VERSION ""

NS_ :

BS_:

BU_: WDAQ MTI600 Datalogger FSGDatalogger GroundSpeed RES Jetson ACM RC Flasher

BO_ 865 Pump1Command: 8 RC
 SG_ Speed : 0|16@1+ (0.001,0.0) [0.0|65.0] "rpm"  Vector__XXX

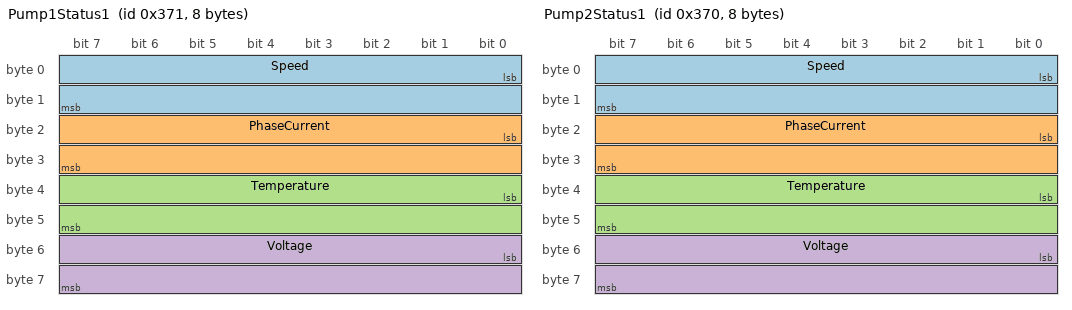
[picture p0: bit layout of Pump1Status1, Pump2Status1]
BO_ 881 Pump1Status1: 8 Pump1
 SG_ Speed : 0|16@1+ (0.001,0.0) [0.0|65.0] "rpm"  Vector__XXX
 SG_ PhaseCurrent : 16|16@1+ (10.0,0.0) [-300.0|300.0] "A"  Vector__XXX
 SG_ Temperature : 32|16@1+ (10.0,0.0) [0.0|200.0] "C"  Vector__XXX
 SG_ Voltage : 48|16@1+ (1.0,0.0) [0.0|65000.0] "mV"  Vector__XXX

BO_ 1025 Pump1Diagnostic: 8 Pump1
 SG_ Header : 0|8@1+ (1.0,0.0) [0.0|256.0] ""  Vector__XXX
 SG_ Data : 8|32@1+ (1.0,0.0) [0.0|16000.0] ""  Vector__XXX

BO_ 864 Pump2Command: 8 RC
 SG_ Speed : 0|16@1+ (0.001,0.0) [0.0|65.0] "rpm"  Vector__XXX

BO_ 880 Pump2Status1: 8 Pump2
 SG_ Speed : 0|16@1+ (0.001,0.0) [0.0|65.0] "rpm"  Vector__XXX
 SG_ PhaseCurrent : 16|16@1+ (10.0,0.0) [-300.0|300.0] "A"  Vector__XXX
 SG_ Temperature : 32|16@1+ (10.0,0.0) [0.0|200.0] "C"  Vector__XXX
 SG_ Voltage : 48|16@1+ (1.0,0.0) [0.0|65000.0] "mV"  Vector__XXX

BO_ 1024 Pump2Diagnostic: 8 Pump2
 SG_ Header : 0|8@1+ (1.0,0.0) [0.0|256.0] ""  Vector__XXX
 SG_ Data : 8|32@1+ (1.0,0.0) [0.0|16000.0] ""  Vector__XXX

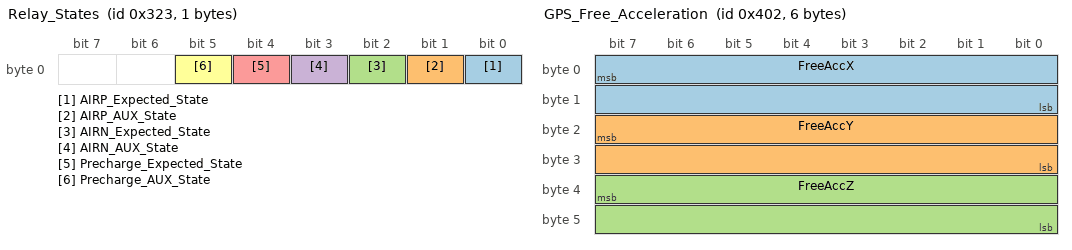
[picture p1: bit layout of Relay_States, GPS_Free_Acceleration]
BO_ 803 Relay_States: 1 ACM
 SG_ AIRP_Expected_State : 0|1@1+ (1.0,0.0) [0.0|1.0] ""  RC,WDAQ
 SG_ AIRP_AUX_State : 1|1@1+ (1.0,0.0) [0.0|1.0] ""  RC,WDAQ
 SG_ AIRN_Expected_State : 2|1@1+ (1.0,0.0) [0.0|1.0] ""  RC,WDAQ
 SG_ AIRN_AUX_State : 3|1@1+ (1.0,0.0) [0.0|1.0] ""  RC,WDAQ
 SG_ Precharge_Expected_State : 4|1@1+ (1.0,0.0) [0.0|1.0] ""  RC,WDAQ
 SG_ Precharge_AUX_State : 5|1@1+ (1.0,0.0) [0.0|1.0] ""  RC,WDAQ

BO_ 1104 Datalogger_Start: 0 RC

BO_ 1026 GPS_Free_Acceleration: 6 MTI600
 SG_ FreeAccX : 7|16@0- (0.00390625,0) [-100.0|100.0] "m/s^2"  WDAQ,Jetson
 SG_ FreeAccY : 23|16@0- (0.00390625,0) [-100.0|100.0] "m/s^2"  WDAQ,Jetson
 SG_ FreeAccZ : 39|16@0- (0.00390625,0) [-100.0|100.0] "m/s^2"  WDAQ,Jetson

BO_ 1045 GPS_StatusWord: 4 MTI600
 SG_ StatusWord : 7|32@0+ (1.0,0) [0.0|4294967295.0] ""  WDAQ,Jetson

BO_ 1046 GPS_Error: 1 MTI600
 SG_ ErrorCode : 7|8@0+ (1.0,0) [0.0|255.0] ""  WDAQ,Jetson

BO_ 1027 GPS_Warning: 1 MTI600
 SG_ WarningCode : 7|8@0+ (1.0,0) [0.0|255.0] ""  WDAQ,Jetson

BO_ 1028 GPS_Sample_Time: 4 MTI600
 SG_ SampleTime : 7|32@0+ (1.0,0) [0.0|4294967295.0] "100us"  WDAQ,Jetson

BO_ 1029 GPS_Group_Counter: 2 MTI600
 SG_ Counter : 7|16@0+ (1.0,0) [0.0|65535.0] ""  WDAQ,Jetson

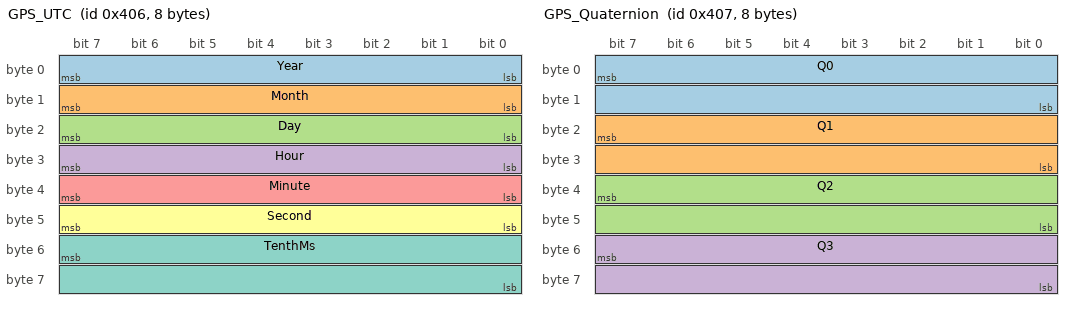
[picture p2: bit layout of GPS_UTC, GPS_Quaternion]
BO_ 1030 GPS_UTC: 8 MTI600
 SG_ Year : 7|8@0+ (1.0,0) [0.0|255.0] ""  WDAQ,Jetson
 SG_ Month : 15|8@0+ (1.0,0) [1.0|12.0] ""  WDAQ,Jetson
 SG_ Day : 23|8@0+ (1.0,0) [1.0|31.0] ""  WDAQ,Jetson
 SG_ Hour : 31|8@0+ (1.0,0) [0.0|24.0] ""  WDAQ,Jetson
 SG_ Minute : 39|8@0+ (1.0,0) [0.0|60.0] ""  WDAQ,Jetson
 SG_ Second : 47|8@0+ (1.0,0) [0.0|60.0] ""  WDAQ,Jetson
 SG_ TenthMs : 55|16@0+ (1.0,0) [0.0|10000.0] "0.1ms"  WDAQ,Jetson

BO_ 1031 GPS_Quaternion: 8 MTI600
 SG_ Q0 : 7|16@0- (3.0517578125e-05,0) [-1.0|1.0] ""  WDAQ,Jetson
 SG_ Q1 : 23|16@0- (3.0517578125e-05,0) [-1.0|1.0] ""  WDAQ,Jetson
 SG_ Q2 : 39|16@0- (3.0517578125e-05,0) [-1.0|1.0] ""  WDAQ,Jetson
 SG_ Q3 : 55|16@0- (3.0517578125e-05,0) [-1.0|1.0] ""  WDAQ,Jetson

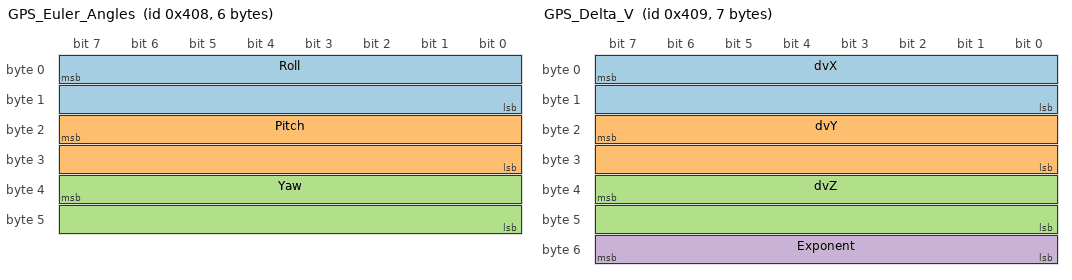
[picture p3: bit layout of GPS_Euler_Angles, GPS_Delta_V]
BO_ 1032 GPS_Euler_Angles: 6 MTI600
 SG_ Roll : 7|16@0- (0.0078125,0) [-180.0|180.0] "deg"  WDAQ,Jetson
 SG_ Pitch : 23|16@0- (0.0078125,0) [-90.0|90.0] "deg"  WDAQ,Jetson
 SG_ Yaw : 39|16@0- (0.0078125,0) [-180.0|180.0] "deg"  WDAQ,Jetson

BO_ 1033 GPS_Delta_V: 7 MTI600
 SG_ dvX : 7|16@0- (7.62939453125e-06,0) [-0.25|0.25] "m/s"  WDAQ,Jetson
 SG_ dvY : 23|16@0- (7.62939453125e-06,0) [-0.25|0.25] "m/s"  WDAQ,Jetson
 SG_ dvZ : 39|16@0- (7.62939453125e-06,0) [-0.25|0.25] "m/s"  WDAQ,Jetson
 SG_ Exponent : 55|8@0+ (1.0,0) [0.0|255.0] ""  WDAQ,Jetson

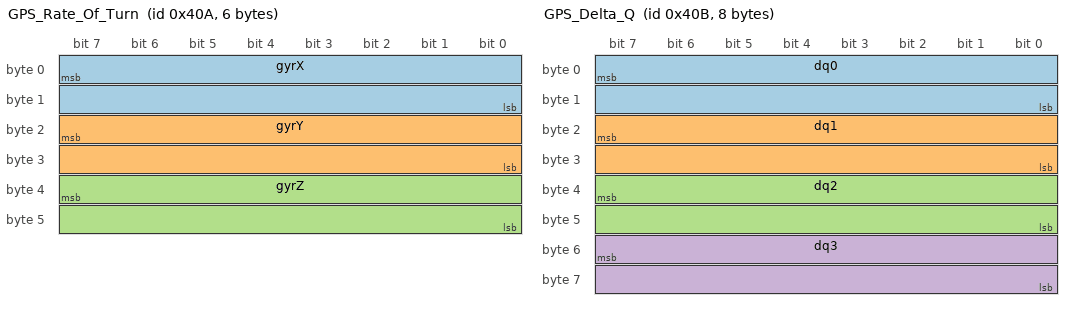
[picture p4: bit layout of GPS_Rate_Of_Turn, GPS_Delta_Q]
BO_ 1034 GPS_Rate_Of_Turn: 6 MTI600
 SG_ gyrX : 7|16@0- (0.001953125,0) [-35.0|35.0] "rad/s"  WDAQ,Jetson
 SG_ gyrY : 23|16@0- (0.001953125,0) [-35.0|35.0] "rad/s"  WDAQ,Jetson
 SG_ gyrZ : 39|16@0- (0.001953125,0) [-35.0|35.0] "rad/s"  WDAQ,Jetson

BO_ 1035 GPS_Delta_Q: 8 MTI600
 SG_ dq0 : 7|16@0- (3.0518509476e-05,0) [-1.0|1.0] ""  WDAQ,Jetson
 SG_ dq1 : 23|16@0- (3.0518509476e-05,0) [-1.0|1.0] ""  WDAQ,Jetson
 SG_ dq2 : 39|16@0- (3.0518509476e-05,0) [-1.0|1.0] ""  WDAQ,Jetson
 SG_ dq3 : 55|16@0- (3.0518509476e-05,0) [-1.0|1.0] ""  WDAQ,Jetson

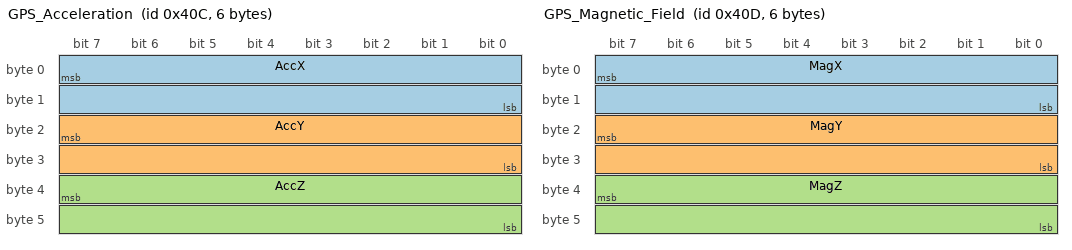
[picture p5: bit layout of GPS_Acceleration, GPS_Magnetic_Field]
BO_ 1036 GPS_Acceleration: 6 MTI600
 SG_ AccX : 7|16@0- (0.00390625,0) [-100.0|100.0] "m/s^2"  WDAQ,Jetson
 SG_ AccY : 23|16@0- (0.00390625,0) [-100.0|100.0] "m/s^2"  WDAQ,Jetson
 SG_ AccZ : 39|16@0- (0.00390625,0) [-100.0|100.0] "m/s^2"  WDAQ,Jetson

BO_ 1037 GPS_Magnetic_Field: 6 MTI600
 SG_ MagX : 7|16@0- (0.0009765625,0) [-32.0|32.0] "a.u."  WDAQ,Jetson
 SG_ MagY : 23|16@0- (0.0009765625,0) [-32.0|32.0] "a.u."  WDAQ,Jetson
 SG_ MagZ : 39|16@0- (0.0009765625,0) [-32.0|32.0] "a.u."  WDAQ,Jetson

BO_ 1038 GPS_Temperature: 2 MTI600
 SG_ Temperature : 7|16@0- (0.00390625,0) [-40.0|85.0] "degC"  WDAQ,Jetson

BO_ 1039 GPS_Baro_Pressure: 4 MTI600
 SG_ Pressure : 7|32@0+ (3.0517578125e-05,0) [30000.0|125000.0] "Pa"  WDAQ,Jetson

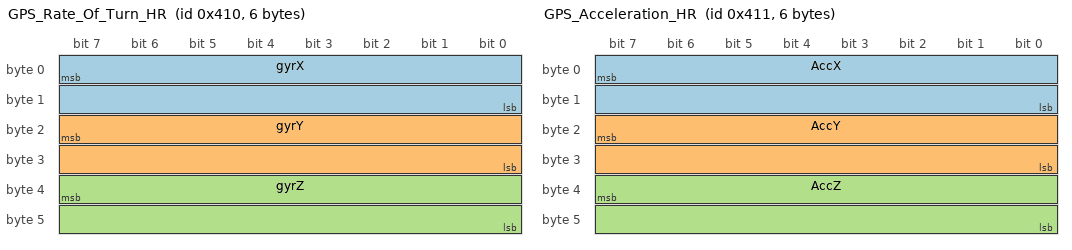
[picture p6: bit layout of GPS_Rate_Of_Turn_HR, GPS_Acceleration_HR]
BO_ 1040 GPS_Rate_Of_Turn_HR: 6 MTI600
 SG_ gyrX : 7|16@0- (0.001953125,0) [-35.0|35.0] "rad/s"  WDAQ,Jetson
 SG_ gyrY : 23|16@0- (0.001953125,0) [-35.0|35.0] "rad/s"  WDAQ,Jetson
 SG_ gyrZ : 39|16@0- (0.001953125,0) [-35.0|35.0] "rad/s"  WDAQ,Jetson

BO_ 1041 GPS_Acceleration_HR: 6 MTI600
 SG_ AccX : 7|16@0- (0.00390625,0) [-100.0|100.0] "m/s^2"  WDAQ,Jetson
 SG_ AccY : 23|16@0- (0.00390625,0) [-100.0|100.0] "m/s^2"  WDAQ,Jetson
 SG_ AccZ : 39|16@0- (0.00390625,0) [-100.0|100.0] "m/s^2"  WDAQ,Jetson

BO_ 1042 GPS_Lat_Lon: 8 MTI600
 SG_ Latitude : 7|32@0- (5.9604644775e-08,0) [-90.0|90.0] "deg"  WDAQ,Jetson
 SG_ Longitude : 39|32@0- (1.1920928955e-07,0) [-180.0|180.0] "deg"  WDAQ,Jetson

BO_ 1043 GPS_Altitude_Ellipsoid: 4 MTI600
 SG_ AltitudeEllipsoid : 7|32@0+ (3.0517578125e-05,0) [0.0|50000.0] "m"  WDAQ,Jetson

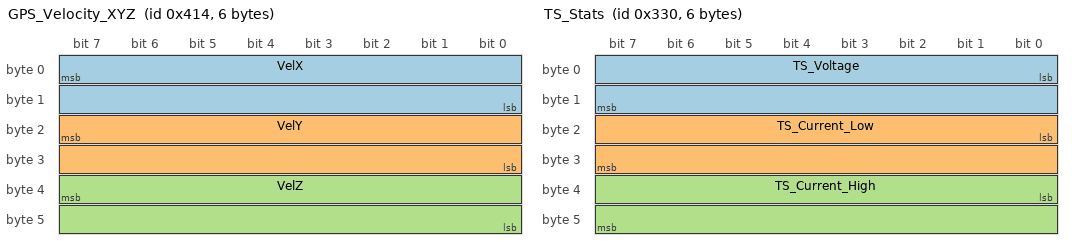
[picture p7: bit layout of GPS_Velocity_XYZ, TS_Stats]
BO_ 1044 GPS_Velocity_XYZ: 6 MTI600
 SG_ VelX : 7|16@0- (0.015625,0) [-500.0|500.0] "m/s"  WDAQ,Jetson
 SG_ VelY : 23|16@0- (0.015625,0) [-500.0|500.0] "m/s"  WDAQ,Jetson
 SG_ VelZ : 39|16@0- (0.015625,0) [-500.0|500.0] "m/s"  WDAQ,Jetson

BO_ 816 TS_Stats: 6 ACM
 SG_ TS_Voltage : 0|16@1+ (1.0,0.0) [0.0|1035.0] "V"  RC,WDAQ
 SG_ TS_Current_Low : 16|16@1- (0.01,0.0) [-32768.0|32767.0] "A"  RC,WDAQ
 SG_ TS_Current_High : 32|16@1- (0.01,0.0) [-32768.0|32767.0] "A"  RC,WDAQ

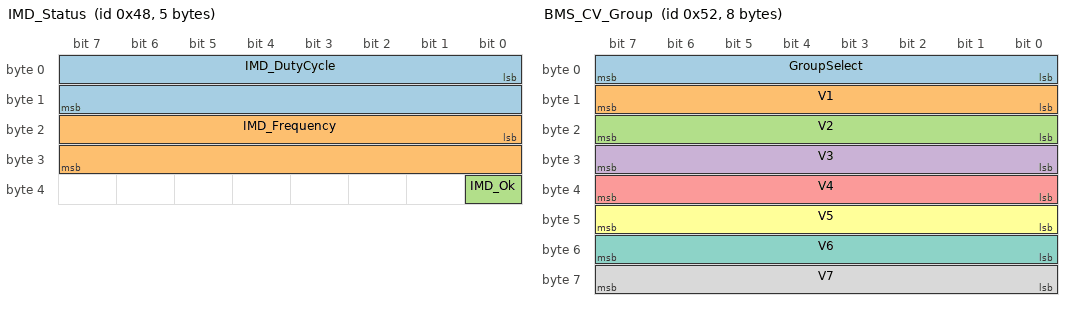
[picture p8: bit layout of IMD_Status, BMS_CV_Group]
BO_ 72 IMD_Status: 5 ACM
 SG_ IMD_DutyCycle : 0|16@1+ (0.01,0.0) [0.0|100.0] "%"  WDAQ
 SG_ IMD_Frequency : 16|16@1+ (0.01,0.0) [0.0|50.0] "Hz"  WDAQ
 SG_ IMD_Ok : 32|1@1+ (1.0,0.0) [0.0|1.0] ""  WDAQ

BO_ 81 BMS_Cell_Open_Wire: 1 ACM
 SG_ Cell : 0|8@1+ (1.0,0.0) [0.0|138.0] ""  WDAQ

BO_ 82 BMS_CV_Group: 8 ACM
 SG_ GroupSelect : 0|8@1+ (1.0,0.0) [0.0|20.0] ""  WDAQ
 SG_ V1 : 8|8@1+ (0.01,3.0) [3.0|4.35] "V"  WDAQ
 SG_ V2 : 16|8@1+ (0.01,3.0) [3.0|4.35] "V"  WDAQ
 SG_ V3 : 24|8@1+ (0.01,3.0) [3.0|4.35] "V"  WDAQ
 SG_ V4 : 32|8@1+ (0.01,3.0) [3.0|4.35] "V"  WDAQ
 SG_ V5 : 40|8@1+ (0.01,3.0) [3.0|4.35] "V"  WDAQ
 SG_ V6 : 48|8@1+ (0.01,3.0) [3.0|4.35] "V"  WDAQ
 SG_ V7 : 56|8@1+ (0.01,3.0) [3.0|4.35] "V"  WDAQ

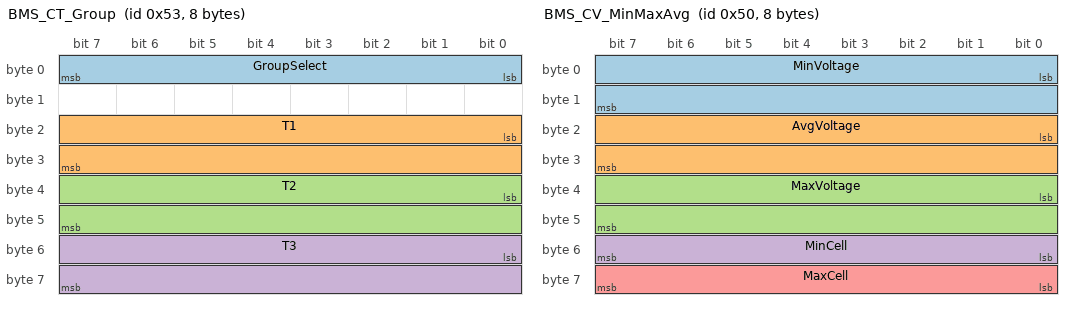
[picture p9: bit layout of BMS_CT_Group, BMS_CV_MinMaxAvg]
BO_ 83 BMS_CT_Group: 8 ACM
 SG_ GroupSelect : 0|8@1+ (1.0,0.0) [0.0|20.0] ""  WDAQ
 SG_ T1 : 16|16@1+ (0.01,0.0) [0.0|100.0] "C"  WDAQ
 SG_ T2 : 32|16@1+ (0.01,0.0) [0.0|100.0] "C"  WDAQ
 SG_ T3 : 48|16@1+ (0.01,0.0) [0.0|100.0] "C"  WDAQ

BO_ 80 BMS_CV_MinMaxAvg: 8 ACM
 SG_ MinVoltage : 0|16@1+ (0.0001,0.0) [0.0|6.5535] "V"  WDAQ
 SG_ AvgVoltage : 16|16@1+ (0.0001,0.0) [0.0|6.5535] "V"  WDAQ
 SG_ MaxVoltage : 32|16@1+ (0.0001,0.0) [0.0|6.5535] "V"  WDAQ
 SG_ MinCell : 48|8@1+ (1.0,0.0) [0.0|138.0] ""  WDAQ
 SG_ MaxCell : 56|8@1+ (1.0,0.0) [0.0|138.0] ""  WDAQ

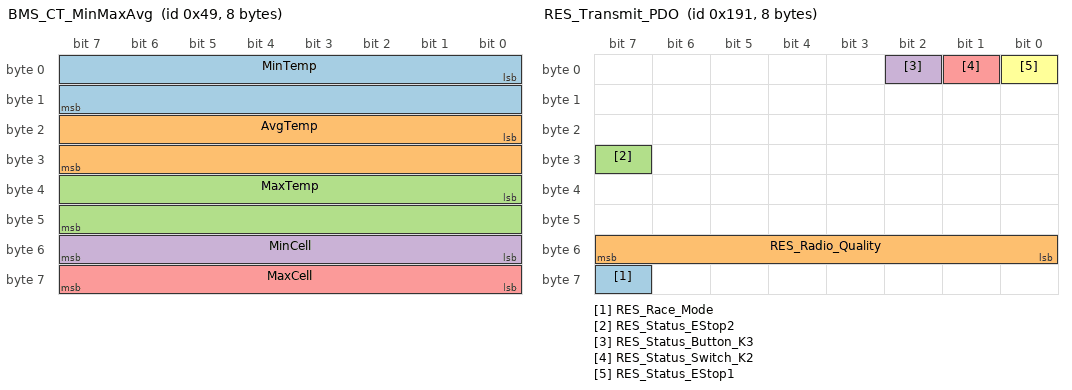
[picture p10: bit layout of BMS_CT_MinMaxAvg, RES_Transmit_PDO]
BO_ 73 BMS_CT_MinMaxAvg: 8 ACM
 SG_ MinTemp : 0|16@1+ (0.01,0.0) [0.0|100.0] "C"  WDAQ
 SG_ AvgTemp : 16|16@1+ (0.01,0.0) [0.0|100.0] "C"  WDAQ
 SG_ MaxTemp : 32|16@1+ (0.01,0.0) [0.0|100.0] "C"  WDAQ
 SG_ MinCell : 48|8@1+ (1.0,0.0) [0.0|138.0] ""  WDAQ
 SG_ MaxCell : 56|8@1+ (1.0,0.0) [0.0|138.0] ""  WDAQ

BO_ 261 DFU_Requested: 1 Flasher
 SG_ DFU_Controller : 0|8@1+ (1.0,0.0) [0.0|4.0] ""  ACM,FC,RC,WDAQ

BO_ 260 DFU_Ack: 0 Flasher

BO_ 117 RC_SDC_State: 1 RC
 SG_ SDC_Point : 0|8@1+ (1.0,0.0) [0.0|255.0] ""  ACM,FC,WDAQ

BO_ 128 RES_Sync: 8 RC

BO_ 401 RES_Transmit_PDO: 8 RES
 SG_ RES_Race_Mode : 63|1@1+ (1.0,0.0) [0.0|1.0] ""  RC
 SG_ RES_Radio_Quality : 48|8@1+ (1.0,0.0) [0.0|100.0] "%"  RC
 SG_ RES_Status_EStop2 : 31|1@1+ (1.0,0.0) [0.0|1.0] ""  RC
 SG_ RES_Status_Button_K3 : 2|1@1+ (1.0,0.0) [0.0|0.0] ""  Jetson,RC
 SG_ RES_Status_Switch_K2 : 1|1@1+ (1.0,0.0) [0.0|1.0] ""  Jetson,RC
 SG_ RES_Status_EStop1 : 0|1@1+ (1.0,0.0) [0.0|1.0] ""  Jetson,RC

BO_ 0 RES_Operational_Mode: 2 RC
 SG_ RES_Node_ID : 8|8@1+ (1.0,0.0) [0.0|64.0] ""  RES
 SG_ RES_Requested_State : 0|8@1+ (1.0,0.0) [0.0|1.0] ""  RES

BO_ 1809 RES_Init: 1 RES
 SG_ RES_Init : 0|8@1+ (1.0,0.0) [0.0|0.0] ""  RC

BO_ 23 Jetson_Error: 1 RC
 SG_ Jetson_Error : 0|8@1+ (1.0,0.0) [0.0|255.0] ""  RC

BO_ 21 ACM_State: 1 ACM
 SG_ ACM_Error : 0|8@1+ (1.0,0.0) [0.0|255.0] ""  RC

BO_ 118 ACM_SDC_State: 1 RC
 SG_ SDC_Point : 0|8@1+ (1.0,0.0) [0.0|255.0] ""  RC,WDAQ

BO_ 24 RC_State: 2 RC
 SG_ RC_State : 0|8@1+ (1.0,0.0) [0.0|7.0] ""  ACM,WDAQ
 SG_ RC_Error : 8|8@1+ (1.0,0.0) [0.0|255.0] ""  ACM,WDAQ

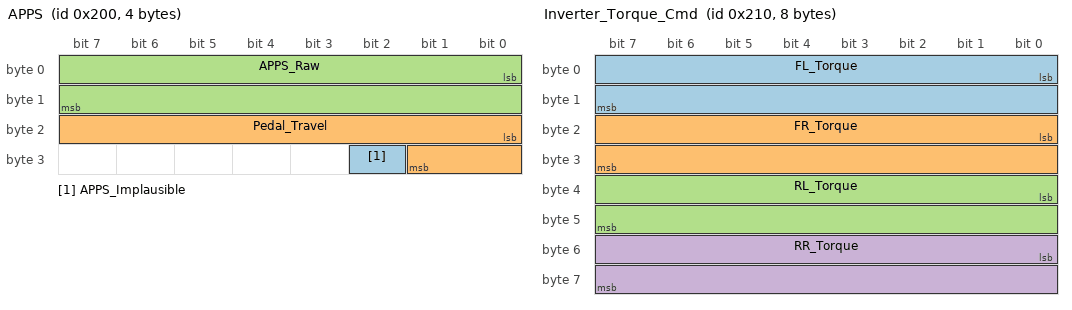
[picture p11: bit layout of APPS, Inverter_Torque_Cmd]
BO_ 512 APPS: 4 RC
 SG_ APPS_Implausible : 26|1@1+ (1.0,0.0) [0.0|1.0] ""  WDAQ
 SG_ Pedal_Travel : 16|10@1+ (0.1,0.0) [0.0|100.0] "%"  WDAQ
 SG_ APPS_Raw : 0|16@1+ (1.0,0.0) [0.0|65535.0] ""  WDAQ

BO_ 530 BSPD: 2 RC
 SG_ BSPD_Current : 0|16@1+ (1.0,0.0) [0.0|4095.0] "counts"  WDAQ

BO_ 528 Inverter_Torque_Cmd: 8 RC
 SG_ FL_Torque : 0|16@1+ (0.2,-6400.0) [-6400.0|6451.0] "Nm"  WDAQ
 SG_ FR_Torque : 16|16@1+ (0.2,-6400.0) [-6400.0|6451.0] "Nm"  WDAQ
 SG_ RL_Torque : 32|16@1+ (0.2,-6400.0) [-6400.0|6451.0] "Nm"  WDAQ
 SG_ RR_Torque : 48|16@1+ (0.2,-6400.0) [-6400.0|6451.0] "Nm"  WDAQ

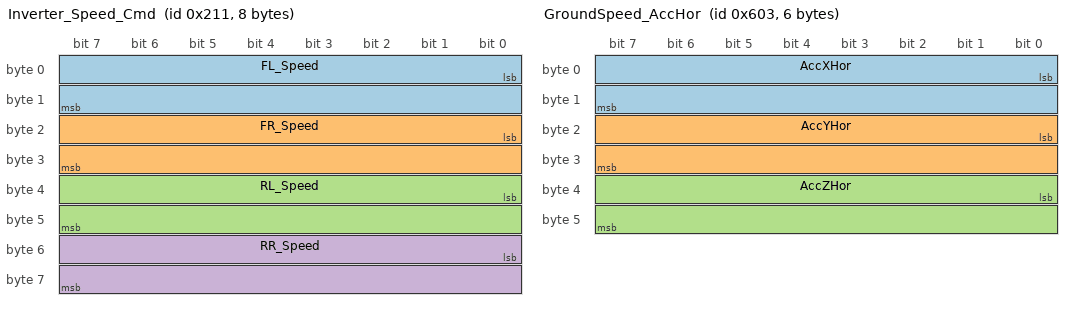
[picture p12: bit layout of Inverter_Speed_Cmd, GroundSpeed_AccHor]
BO_ 529 Inverter_Speed_Cmd: 8 RC
 SG_ FL_Speed : 0|16@1+ (1.0,-32000.0) [-32000.0|32255.0] "RPM"  WDAQ
 SG_ FR_Speed : 16|16@1+ (1.0,-32000.0) [-32000.0|32255.0] "RPM"  WDAQ
 SG_ RL_Speed : 32|16@1+ (1.0,-32000.0) [-32000.0|32255.0] "RPM"  WDAQ
 SG_ RR_Speed : 48|16@1+ (1.0,-32000.0) [-32000.0|32255.0] "RPM"  WDAQ

BO_ 1538 GroundSpeed_PitchAndRoll: 4 GroundSpeed
 SG_ Roll : 0|16@1- (0.003,0.0) [-90.0|90.0] "deg"  WDAQ,Jetson
 SG_ Pitch : 16|16@1- (0.003,0.0) [-90.0|90.0] "deg"  WDAQ,Jetson

BO_ 1539 GroundSpeed_AccHor: 6 GroundSpeed
 SG_ AccXHor : 0|16@1- (0.02,0.0) [-200.0|200.0] "m/s^2"  WDAQ,Jetson
 SG_ AccYHor : 16|16@1- (0.02,0.0) [-200.0|200.0] "m/s^2"  WDAQ,Jetson
 SG_ AccZHor : 32|16@1- (0.02,0.0) [-200.0|200.0] "m/s^2"  WDAQ,Jetson

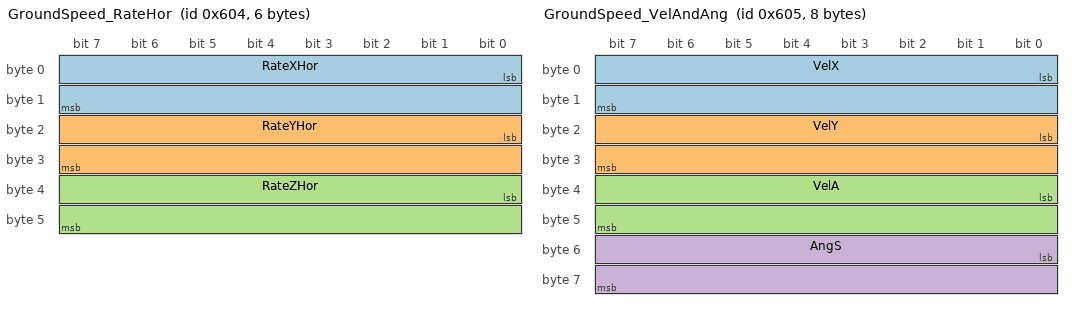
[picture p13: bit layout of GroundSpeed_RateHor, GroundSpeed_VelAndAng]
BO_ 1540 GroundSpeed_RateHor: 6 GroundSpeed
 SG_ RateXHor : 0|16@1- (0.02,0.0) [-500.0|500.0] "deg/s"  WDAQ,Jetson
 SG_ RateYHor : 16|16@1- (0.02,0.0) [-500.0|500.0] "deg/s"  WDAQ,Jetson
 SG_ RateZHor : 32|16@1- (0.02,0.0) [-500.0|500.0] "deg/s"  WDAQ,Jetson

BO_ 1541 GroundSpeed_VelAndAng: 8 GroundSpeed
 SG_ VelX : 0|16@1- (0.02,0.0) [-450.0|450.0] "km/h"  WDAQ,Jetson
 SG_ VelY : 16|16@1- (0.02,0.0) [-100.0|100.0] "km/h"  WDAQ,Jetson
 SG_ VelA : 32|16@1- (0.02,0.0) [0.0|450.0] "km/h"  WDAQ,Jetson
 SG_ AngS : 48|16@1- (0.003,0.0) [-40.0|40.0] "deg"  WDAQ,Jetson

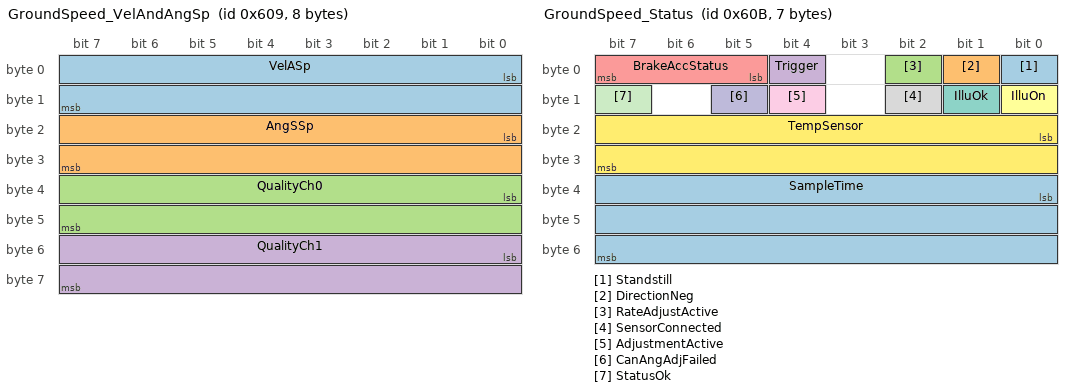
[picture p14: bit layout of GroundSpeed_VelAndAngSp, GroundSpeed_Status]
BO_ 1545 GroundSpeed_VelAndAngSp: 8 GroundSpeed
 SG_ VelASp : 0|16@1- (0.02,0.0) [0.0|450.0] "km/h"  WDAQ,Jetson
 SG_ AngSSp : 16|16@1- (0.003,0.0) [-40.0|40.0] "deg"  WDAQ,Jetson
 SG_ QualityCh0 : 32|16@1+ (1.0,0.0) [0.0|65535.0] ""  WDAQ,Jetson
 SG_ QualityCh1 : 48|16@1+ (1.0,0.0) [0.0|65535.0] ""  WDAQ,Jetson

BO_ 1547 GroundSpeed_Status: 7 GroundSpeed
 SG_ Standstill : 0|1@1+ (1.0,0.0) [0.0|1.0] ""  WDAQ,Jetson
 SG_ DirectionNeg : 1|1@1+ (1.0,0.0) [0.0|1.0] ""  WDAQ,Jetson
 SG_ RateAdjustActive : 2|1@1+ (1.0,0.0) [0.0|1.0] ""  WDAQ,Jetson
 SG_ Trigger : 4|1@1+ (1.0,0.0) [0.0|1.0] ""  WDAQ,Jetson
 SG_ BrakeAccStatus : 5|3@1+ (1.0,0.0) [0.0|5.0] ""  WDAQ,Jetson
 SG_ IlluOn : 8|1@1+ (1.0,0.0) [0.0|1.0] ""  WDAQ,Jetson
 SG_ IlluOk : 9|1@1+ (1.0,0.0) [0.0|1.0] ""  WDAQ,Jetson
 SG_ SensorConnected : 10|1@1+ (1.0,0.0) [0.0|1.0] ""  WDAQ,Jetson
 SG_ AdjustmentActive : 12|1@1+ (1.0,0.0) [0.0|1.0] ""  WDAQ,Jetson
 SG_ CanAngAdjFailed : 13|1@1+ (1.0,0.0) [0.0|1.0] ""  WDAQ,Jetson
 SG_ StatusOk : 15|1@1+ (1.0,0.0) [0.0|1.0] ""  WDAQ,Jetson
 SG_ TempSensor : 16|16@1- (0.1,0.0) [-20.0|85.0] "C"  WDAQ,Jetson
 SG_ SampleTime : 32|24@1+ (0.001,0.0) [0.0|16777.215] "s"  WDAQ,Jetson

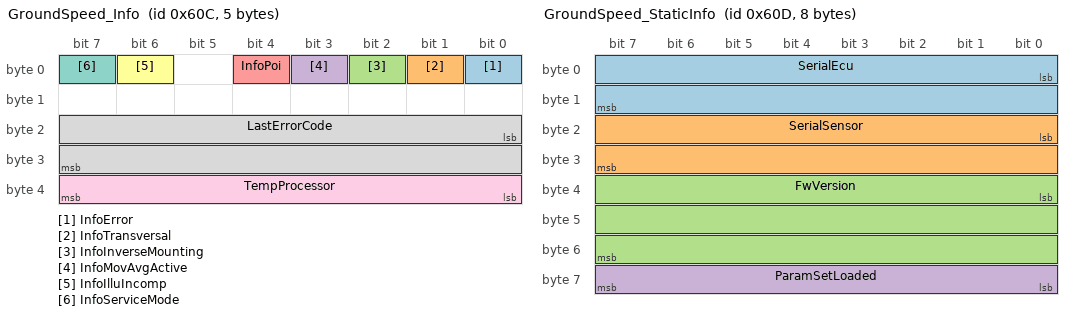
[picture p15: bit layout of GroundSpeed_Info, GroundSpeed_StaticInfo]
BO_ 1548 GroundSpeed_Info: 5 GroundSpeed
 SG_ InfoError : 0|1@1+ (1.0,0.0) [0.0|1.0] ""  WDAQ,Jetson
 SG_ InfoTransversal : 1|1@1+ (1.0,0.0) [0.0|1.0] ""  WDAQ,Jetson
 SG_ InfoInverseMounting : 2|1@1+ (1.0,0.0) [0.0|1.0] ""  WDAQ,Jetson
 SG_ InfoMovAvgActive : 3|1@1+ (1.0,0.0) [0.0|1.0] ""  WDAQ,Jetson
 SG_ InfoPoi : 4|1@1+ (1.0,0.0) [0.0|1.0] ""  WDAQ,Jetson
 SG_ InfoIlluIncomp : 6|1@1+ (1.0,0.0) [0.0|1.0] ""  WDAQ,Jetson
 SG_ InfoServiceMode : 7|1@1+ (1.0,0.0) [0.0|1.0] ""  WDAQ,Jetson
 SG_ LastErrorCode : 16|16@1+ (1.0,0.0) [0.0|65535.0] ""  WDAQ,Jetson
 SG_ TempProcessor : 32|8@1- (1.0,0.0) [-128.0|127.0] "C"  WDAQ,Jetson

BO_ 1549 GroundSpeed_StaticInfo: 8 GroundSpeed
 SG_ SerialEcu : 0|16@1+ (1.0,0.0) [0.0|65535.0] ""  WDAQ,Jetson
 SG_ SerialSensor : 16|16@1+ (1.0,0.0) [0.0|65535.0] ""  WDAQ,Jetson
 SG_ FwVersion : 32|24@1+ (1.0,0.0) [0.0|16777215.0] ""  WDAQ,Jetson
 SG_ ParamSetLoaded : 56|8@1+ (1.0,0.0) [0.0|255.0] ""  WDAQ,Jetson

BA_DEF_ BU_  "ECU" STRING ;
BA_DEF_ BO_  "VFrameFormat" ENUM  "StandardCAN","ExtendedCAN";
BA_DEF_  "BusType" STRING ;
BA_DEF_DEF_  "ECU" "";
BA_DEF_DEF_  "VFrameFormat" "StandardCAN";
BA_DEF_DEF_  "BusType" "CAN";

BA_ "ECU" BU_ WDAQ "WDAQ";
BA_ "ECU" BU_ MTI600 "MTI600";
BA_ "ECU" BU_ Datalogger "Datalogger";
BA_ "ECU" BU_ FSGDatalogger "FSGDatalogger";
BA_ "ECU" BU_ GroundSpeed "GroundSpeed";
BA_ "ECU" BU_ RES "RES";
BA_ "ECU" BU_ Jetson "Jetson";
BA_ "ECU" BU_ ACM "ACM";
BA_ "ECU" BU_ RC "RC";
BA_ "ECU" BU_ Flasher "Flasher";

VAL_ 261 DFU_Controller 4 "WDAQ" 3 "RC" 2 "FC" 1 "ACM" 0 "INVALID" ;
VAL_ 117 SDC_Point 17 "TSMS" 16 "CHARGING_INTERLOCK" 15 "HV_INTERLOCK" 14 "IMD_RELAY" 13 "BMS_RELAY" 12 "HVBB" 11 "FRONT_RIGHT_MOTOR_INTERLOCK" 10 "CSB" 9 "BOTS" 8 "FRONT_LEFT_MOTOR_INTERLOCK" 7 "FC_RELAY" 6 "INERTIA_SWITCH" 5 "RES" 4 "REAR_MOTOR_INTERLOCK" 3 "SDB" 2 "RC_RELAY" 1 "BSPD" 0 "CLOSED" ;
VAL_ 401 RES_Status_EStop2 1 "Enabled" 0 "Disabled" ;
VAL_ 401 RES_Status_Button_K3 1 "Enabled" 0 "Disabled" ;
VAL_ 401 RES_Status_Switch_K2 1 "Enabled" 0 "Disabled" ;
VAL_ 401 RES_Status_EStop1 1 "Enabled" 0 "Disabled" ;
VAL_ 0 RES_Node_ID 17 "Node_ID_11" 0 "All" ;
VAL_ 0 RES_Requested_State 128 "Reset" 1 "Operational" ;
VAL_ 21 ACM_Error 17 "PCAN_WATCHDOG" 16 "ICAN_WATCHDOG" 15 "RCAN_WATCHDOG" 14 "PRECHARGE_FAILURE" 13 "SDC_AFTER_HVBB" 12 "SDC_AFTER_TSMS" 11 "SDC_AFTER_CHARGING_INTERLOCK" 10 "SDC_AFTER_HV_INTERLOCK" 9 "BMS_CELL_OPEN_WIRE" 8 "BMS_OVERTEMP" 7 "BMS_UNDERVOLT" 6 "BMS_OVERVOLT" 5 "IMD_ERROR" 4 "IMD_RESISTANCE_LOW" 3 "PRECHARGE_IMPLAUSIBILITY" 2 "AIRN_IMPLAUSIBILITY" 1 "AIRP_IMPLAUSIBILITY" 0 "NONE" ;
VAL_ 118 SDC_Point 17 "TSMS" 16 "CHARGING_INTERLOCK" 15 "HV_INTERLOCK" 14 "IMD_RELAY" 13 "BMS_RELAY" 12 "HVBB" 11 "FRONT_RIGHT_MOTOR_INTERLOCK" 10 "CSB" 9 "BOTS" 8 "FRONT_LEFT_MOTOR_INTERLOCK" 7 "FC_RELAY" 6 "INERTIA_SWITCH" 5 "RES" 4 "REAR_MOTOR_INTERLOCK" 3 "SDB" 2 "RC_RELAY" 1 "BSPD" 0 "CLOSED" ;
VAL_ 24 RC_State 9 "AMS_FAULT" 8 "AS_FINISHED" 7 "AS_EMERGENCY" 6 "DISCHARGE" 5 "DRIVE" 4 "TS" 3 "EBS_CHECK" 2 "PRECHARGE" 1 "LV" 0 "LV_OFF" ;
VAL_ 24 RC_Error 1 "AMS_FAULT" 0 "NONE" ;

VAL_TABLE_ GPS_FilterMode 3 "WithGNSS" 1 "Coasting" 0 "NoGNSS" ;
VAL_TABLE_ GPS_Error 42 "BufferOverflow" 41 "DataOverflow" 40 "DeviceError" 33 "InvalidParameter" 32 "BaudrateOutOfRange" 30 "TimerOverflow" 4 "MessageSentInvalid" 3 "PeriodSentOutOfRange" ;
VAL_TABLE_ RTK_Status 2 "RTK_FIXED" 1 "RTK_FLOATING" 0 "NO_RTK" ;
VAL_TABLE_ DFU_Controller 4 "WDAQ" 3 "RC" 2 "FC" 1 "ACM" 0 "INVALID" ;
VAL_TABLE_ SDC_Point 17 "TSMS" 16 "CHARGING_INTERLOCK" 15 "HV_INTERLOCK" 14 "IMD_RELAY" 13 "BMS_RELAY" 12 "HVBB" 11 "FRONT_RIGHT_MOTOR_INTERLOCK" 10 "CSB" 9 "BOTS" 8 "FRONT_LEFT_MOTOR_INTERLOCK" 7 "FC_RELAY" 6 "INERTIA_SWITCH" 5 "RES" 4 "REAR_MOTOR_INTERLOCK" 3 "SDB" 2 "RC_RELAY" 1 "BSPD" 0 "CLOSED" ;
VAL_TABLE_ RES_Status 1 "Enabled" 0 "Disabled" ;
VAL_TABLE_ RES_Requested_State 128 "Reset" 1 "Operational" ;
VAL_TABLE_ RES_Node_ID 17 "Node_ID_11" 0 "All" ;
VAL_TABLE_ ACM_Error 17 "PCAN_WATCHDOG" 16 "ICAN_WATCHDOG" 15 "RCAN_WATCHDOG" 14 "PRECHARGE_FAILURE" 13 "SDC_AFTER_HVBB" 12 "SDC_AFTER_TSMS" 11 "SDC_AFTER_CHARGING_INTERLOCK" 10 "SDC_AFTER_HV_INTERLOCK" 9 "BMS_CELL_OPEN_WIRE" 8 "BMS_OVERTEMP" 7 "BMS_UNDERVOLT" 6 "BMS_OVERVOLT" 5 "IMD_ERROR" 4 "IMD_RESISTANCE_LOW" 3 "PRECHARGE_IMPLAUSIBILITY" 2 "AIRN_IMPLAUSIBILITY" 1 "AIRP_IMPLAUSIBILITY" 0 "NONE" ;
VAL_TABLE_ RC_State 9 "AMS_FAULT" 8 "AS_FINISHED" 7 "AS_EMERGENCY" 6 "DISCHARGE" 5 "DRIVE" 4 "TS" 3 "EBS_CHECK" 2 "PRECHARGE" 1 "LV" 0 "LV_OFF" ;
VAL_TABLE_ RC_Error 1 "AMS_FAULT" 0 "NONE" ;
VAL_TABLE_ InverterStatus 3 "NO_DATA" 2 "RESERVED" 1 "POWER_SECTION_ENABLED" 0 "POWER_SECTION_INHIBITED" ;
VAL_TABLE_ InverterReady 3 "NO_DATA" 2 "RESERVED" 1 "READY" 0 "NOT_READY" ;
VAL_TABLE_ InverterErrorStatus 3 "NO_DATA" 2 "WARNING" 1 "ERROR" 0 "NO_ERROR" ;
VAL_TABLE_ InverterLimitationStatus 3 "NO_DATA" 2 "RESERVED" 1 "LIMIT_ACTIVE" 0 "NO_LIMIT_ACTIVE" ;
VAL_TABLE_ InverterEnabledDisabled 3 "NO_DATA" 2 "RESERVED" 1 "ENABLED" 0 "DISABLED" ;
VAL_TABLE_ DC_Link_Charge_State 3 "No_Data" 2 "Discharge_Complete" 1 "Precharge_Complete" 0 "Precharge_Not_Complete" ;
VAL_TABLE_ Error_Lamp 3 "No_Data" 2 "RESERVED" 1 "On" 0 "Off" ;
VAL_TABLE_ Device_State 3 "No_Data" 2 "RESERVED" 1 "Initialization_Active" 0 "Initialization_Complete" ;
VAL_TABLE_ Clamp15_Status 3 "NO_DATA" 2 "RESERVED" 1 "ENABLED" 0 "DISABLED" ;
VAL_TABLE_ DCU_Control 3 "NO_DATA" 2 "RESERVED" 1 "ENABLE" 0 "DISABLE" ;
